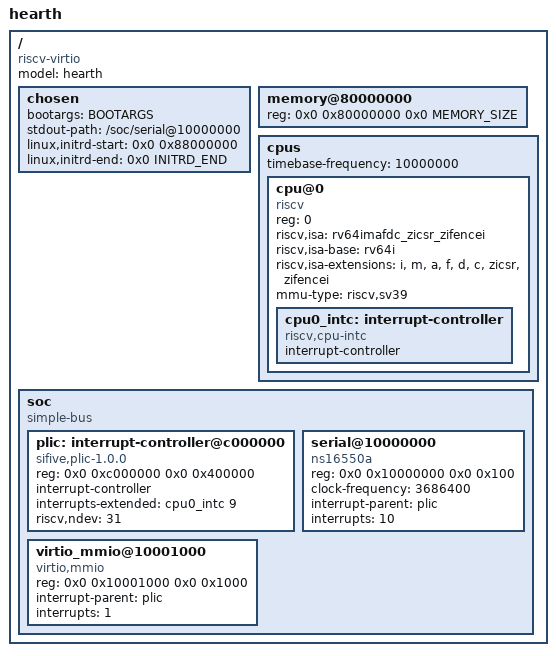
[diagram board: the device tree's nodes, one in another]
/* Hearth's riscv64 machine (src/arch/riscv64), for --linux --dtb. RAM is
 * at 0x80000000; Hearth puts this DTB at its base and the initramfs 128M
 * in. MEMORY_SIZE, INITRD_END and BOOTARGS are filled in by run-riscv64.sh;
 * a disk would be on the virtio_mmio node. */
/dts-v1/;

/ {
	#address-cells = <2>;
	#size-cells = <2>;
	compatible = "riscv-virtio";
	model = "hearth";

	chosen {
		bootargs = BOOTARGS;
		stdout-path = "/soc/serial@10000000";
		linux,initrd-start = <0x0 0x88000000>;
		linux,initrd-end = <0x0 INITRD_END>;
	};

	memory@80000000 {
		device_type = "memory";
		reg = <0x0 0x80000000 0x0 MEMORY_SIZE>;
	};

	cpus {
		#address-cells = <1>;
		#size-cells = <0>;
		/* The guest reads the host's time CSR: QEMU virt's 10 MHz. */
		timebase-frequency = <10000000>;

		cpu@0 {
			device_type = "cpu";
			reg = <0>;
			compatible = "riscv";
			/* What KVM gives a guest by default. riscv,isa is for
			 * kernels older than isa-base/isa-extensions. */
			riscv,isa = "rv64imafdc_zicsr_zifencei";
			riscv,isa-base = "rv64i";
			riscv,isa-extensions = "i", "m", "a", "f", "d", "c", "zicsr", "zifencei";
			mmu-type = "riscv,sv39";
			status = "okay";

			cpu0_intc: interrupt-controller {
				compatible = "riscv,cpu-intc";
				#interrupt-cells = <1>;
				interrupt-controller;
			};
		};
	};

	soc {
		compatible = "simple-bus";
		#address-cells = <2>;
		#size-cells = <2>;
		ranges;

		plic: interrupt-controller@c000000 {
			compatible = "sifive,plic-1.0.0", "riscv,plic0";
			reg = <0x0 0xc000000 0x0 0x400000>;
			#address-cells = <0>;
			#interrupt-cells = <1>;
			interrupt-controller;
			/* Only the S-mode external interrupt: context 0. */
			interrupts-extended = <&cpu0_intc 9>;
			riscv,ndev = <31>;
		};

		serial@10000000 {
			compatible = "ns16550a";
			reg = <0x0 0x10000000 0x0 0x100>;
			clock-frequency = <3686400>;
			interrupt-parent = <&plic>;
			interrupts = <10>;
		};

		virtio_mmio@10001000 {
			compatible = "virtio,mmio";
			reg = <0x0 0x10001000 0x0 0x1000>;
			interrupt-parent = <&plic>;
			interrupts = <1>;
		};
	};
};
